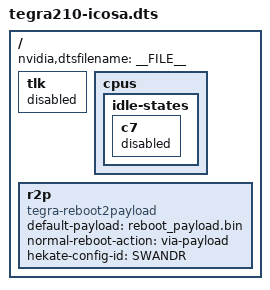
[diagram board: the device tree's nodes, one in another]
/*
 * arch/arm64/boot/dts/tegra210-icosa.dts
 *
 * Copyright (c) 2014-2016, NVIDIA CORPORATION.  All rights reserved.
 *
 * This program is free software; you can redistribute it and/or modify
 * it under the terms of the GNU General Public License as published by
 * the Free Software Foundation; version 2 of the License.
 *
 * This program is distributed in the hope that it will be useful, but WITHOUT
 * ANY WARRANTY; without even the implied warranty of MERCHANTABILITY or
 * FITNESS FOR A PARTICULAR PURPOSE.  See the GNU General Public License for
 * more details.
 *
 */

#include "tegra210-icosa-common.dtsi"
#include "tegra210-icosa-common-disp.dtsi"
#include "icosa-platforms/tegra210-icosa-power-tree.dtsi"
#include "icosa-platforms/tegra210-icosa-emc.dtsi"
#include "icosa-platforms/tegra210-icosa-sensor.dtsi"

/ {
	nvidia,dtsfilename = __FILE__;

	tlk {
		status = "disabled"; // FIXME: needs keys, where are they
	};

	cpus {
		idle-states {
			c7 {
				status = "disabled"; // FIXME: enabling causes crashes on cpu idle
			};
		};
	};

	r2p {
		compatible = "tegra-reboot2payload";
		status = "okay";
		default-payload = "reboot_payload.bin";
		// This can be either "bootloader" to boot payload, or "via-payload" to also apply hekate config.
		// Any other string will reboot normally.
		normal-reboot-action = "via-payload";
		hekate-config-id = "SWANDR";
	};
};
